AUTOSAR XML (schema 00050)
package /IBNvBlkSWC_5
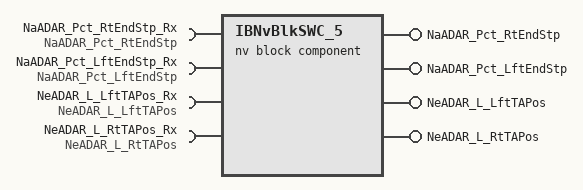
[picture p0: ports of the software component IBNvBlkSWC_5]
  nv block sw component type IBNvBlkSWC_5
    provide port NaADAR_Pct_RtEndStp: nv-provide-com-spec{ram-block-init-value=ArrayValues:[ArrayElement0:0, ArrayElement1:0, ArrayElement2:0, ArrayElement3:0], rom-block-init-value=ArrayValues:[ArrayElement0:0, ArrayElement1:0, ArrayElement2:0, ArrayElement3:0], variable=NaADAR_Pct_RtEndStp}, provided-interface=NaADAR_Pct_RtEndStp
    require port NaADAR_Pct_RtEndStp_Rx: nv-require-com-spec{init-value=ArrayValues:[ArrayElement0:0, ArrayElement1:0, ArrayElement2:0, ArrayElement3:0], variable=NaADAR_Pct_RtEndStp}, required-interface=NaADAR_Pct_RtEndStp
    provide port NaADAR_Pct_LftEndStp: nv-provide-com-spec{ram-block-init-value=ArrayValues:[ArrayElement0:0, ArrayElement1:0, ArrayElement2:0, ArrayElement3:0], rom-block-init-value=ArrayValues:[ArrayElement0:0, ArrayElement1:0, ArrayElement2:0, ArrayElement3:0], variable=NaADAR_Pct_LftEndStp}, provided-interface=NaADAR_Pct_LftEndStp
    require port NaADAR_Pct_LftEndStp_Rx: nv-require-com-spec{init-value=ArrayValues:[ArrayElement0:0, ArrayElement1:0, ArrayElement2:0, ArrayElement3:0], variable=NaADAR_Pct_LftEndStp}, required-interface=NaADAR_Pct_LftEndStp
    provide port NeADAR_L_LftTAPos: nv-provide-com-spec{ram-block-init-value=Value:0, rom-block-init-value=Value:0, variable=NeADAR_L_LftTAPos}, provided-interface=NeADAR_L_LftTAPos
    require port NeADAR_L_LftTAPos_Rx: nv-require-com-spec{init-value=Value:0, variable=NeADAR_L_LftTAPos}, required-interface=NeADAR_L_LftTAPos
    provide port NeADAR_L_RtTAPos: nv-provide-com-spec{ram-block-init-value=Value:0, rom-block-init-value=Value:0, variable=NeADAR_L_RtTAPos}, provided-interface=NeADAR_L_RtTAPos
    require port NeADAR_L_RtTAPos_Rx: nv-require-com-spec{init-value=Value:0, variable=NeADAR_L_RtTAPos}, required-interface=NeADAR_L_RtTAPos
    behavior IB_NvBlkSWC_5: data-type-mapping=NVM_DataMappingSet, handle-termination-and-restart=NO-SUPPORT
    nv block descriptor ExpendableNonVolatile_Descr_Core5: support-dirty-flag=true
      nv-block-data-mappings:
        {nv-ram-block-element=autosar-variable-in-impl-datatype={root-variable-data-prototype=ExpendableNonVolatile_RamBlock_Core5, target-data-prototype=ExpendableNonVolatile_Ram_Core5/NaADAR_Pct_RtEndStp}, read-nv-data=NaADAR_Pct_RtEndStp.NaADAR_Pct_RtEndStp}
        {nv-ram-block-element=autosar-variable-in-impl-datatype={root-variable-data-prototype=ExpendableNonVolatile_RamBlock_Core5, target-data-prototype=ExpendableNonVolatile_Ram_Core5/NaADAR_Pct_RtEndStp}, written-nv-data=NaADAR_Pct_RtEndStp_Rx.NaADAR_Pct_RtEndStp}
        {nv-ram-block-element=autosar-variable-in-impl-datatype={root-variable-data-prototype=ExpendableNonVolatile_RamBlock_Core5, target-data-prototype=ExpendableNonVolatile_Ram_Core5/NaADAR_Pct_LftEndStp}, read-nv-data=NaADAR_Pct_LftEndStp.NaADAR_Pct_LftEndStp}
        {nv-ram-block-element=autosar-variable-in-impl-datatype={root-variable-data-prototype=ExpendableNonVolatile_RamBlock_Core5, target-data-prototype=ExpendableNonVolatile_Ram_Core5/NaADAR_Pct_LftEndStp}, written-nv-data=NaADAR_Pct_LftEndStp_Rx.NaADAR_Pct_LftEndStp}
        {nv-ram-block-element=autosar-variable-in-impl-datatype={root-variable-data-prototype=ExpendableNonVolatile_RamBlock_Core5, target-data-prototype=ExpendableNonVolatile_Ram_Core5/NeADAR_L_LftTAPos}, read-nv-data=NeADAR_L_LftTAPos.NeADAR_L_LftTAPos}
        {nv-ram-block-element=autosar-variable-in-impl-datatype={root-variable-data-prototype=ExpendableNonVolatile_RamBlock_Core5, target-data-prototype=ExpendableNonVolatile_Ram_Core5/NeADAR_L_LftTAPos}, written-nv-data=NeADAR_L_LftTAPos_Rx.NeADAR_L_LftTAPos}
        {nv-ram-block-element=autosar-variable-in-impl-datatype={root-variable-data-prototype=ExpendableNonVolatile_RamBlock_Core5, target-data-prototype=ExpendableNonVolatile_Ram_Core5/NeADAR_L_RtTAPos}, read-nv-data=NeADAR_L_RtTAPos.NeADAR_L_RtTAPos}
        {nv-ram-block-element=autosar-variable-in-impl-datatype={root-variable-data-prototype=ExpendableNonVolatile_RamBlock_Core5, target-data-prototype=ExpendableNonVolatile_Ram_Core5/NeADAR_L_RtTAPos}, written-nv-data=NeADAR_L_RtTAPos_Rx.NeADAR_L_RtTAPos}
      nv block needs NvBlockNeeds: calc-ram-block-crc=false, check-static-block-id=false, readonly=false, resistant-to-changed-sw=false, restore-at-start=true, store-at-shutdown=true, store-cyclic=false, store-emergency=false, store-immediate=false, use-auto-validation-at-shut-down=false, use-crc-comp-mechanism=true, write-only-once=false, write-verification=false
      ram block ExpendableNonVolatile_RamBlock_Core5: type=ExpendableNonVolatile_Ram_Core5, init-value={short-label=ExpendableNonVolatile_Ram_Core5, fields=[NaADAR_Pct_RtEndStp:[ArrayElement0:0, ArrayElement1:0, ArrayElement2:0, ArrayElement3:0], NaADAR_Pct_LftEndStp:[ArrayElement0:0, ArrayElement1:0, ArrayElement2:0, ArrayElement3:0], NeADAR_L_LftTAPos:0, NeADAR_L_RtTAPos:0, Reserved1:0, Reserved2:0, Reserved3:0, Reserved4:0, Reserved5:0, Reserved6:0, Reserved7:0, Reserved8:0, Reserved9:0, Reserved10:0, Reserved11:0, Reserved12:0, Reserved13:0, Reserved14:0, Reserved15:0, Reserved16:0, Reserved17:0, Reserved18:0, Reserved19:0, Reserved20:0, Reserved21:0, Reserved22:0, Reserved23:0, Reserved24:0]}
      rom block ExpendableNonVolatile_RomBlock_Core5: type=ExpendableNonVolatile_Rom_Core5, init-value={short-label=ExpendableNonVolatile_Rom_Core5, fields=[NaADAR_Pct_RtEndStp:[ArrayElement0:0, ArrayElement1:0, ArrayElement2:0, ArrayElement3:0], NaADAR_Pct_LftEndStp:[ArrayElement0:0, ArrayElement1:0, ArrayElement2:0, ArrayElement3:0], NeADAR_L_LftTAPos:0, NeADAR_L_RtTAPos:0, Reserved1:0, Reserved2:0, Reserved3:0, Reserved4:0, Reserved5:0, Reserved6:0, Reserved7:0, Reserved8:0, Reserved9:0, Reserved10:0, Reserved11:0, Reserved12:0, Reserved13:0, Reserved14:0, Reserved15:0, Reserved16:0, Reserved17:0, Reserved18:0, Reserved19:0, Reserved20:0, Reserved21:0, Reserved22:0, Reserved23:0, Reserved24:0]}
package /IFEepNVBlk_5
  impl type ExpendableNonVolatile_Ram_Core5: category=STRUCTURE
    28 x element, all with category=TYPE_REFERENCE:
      NaADAR_Pct_RtEndStp: implementation-data-type=rt_Array_Float_4
      NaADAR_Pct_LftEndStp: implementation-data-type=rt_Array_Float_4
      NeADAR_L_LftTAPos: implementation-data-type=float32
      NeADAR_L_RtTAPos: implementation-data-type=float32
      Reserved{1..24}: implementation-data-type=uint8
  impl type ExpendableNonVolatile_Rom_Core5: category=STRUCTURE
    28 x element, all with category=TYPE_REFERENCE:
      NaADAR_Pct_RtEndStp: implementation-data-type=rt_Array_Float_4
      NaADAR_Pct_LftEndStp: implementation-data-type=rt_Array_Float_4
      NeADAR_L_LftTAPos: implementation-data-type=float32
      NeADAR_L_RtTAPos: implementation-data-type=float32
      Reserved{1..24}: implementation-data-type=uint8
